# apollo3 register map
Vendor: Ambiq Micro; Series: Apollo; File version: 1.0
CPU: CM4 r1p0, little endian, MPU, FPU, 3 interrupt priority bits
Registers are 32-bit, read-write, reset 0x0 unless marked. A register's access mark holds for its fields unless they carry their own. Offsets are from the block's base; [hi:lo] are bit positions; {n}, {i} and the like mark numbered series; 'fields as' and 'values as' point back to an identical list.

## PWRCTRL — PWR Controller Register Bank
Base 0x40021000
0x00 SUPPLYSRC — Voltage Regulator Select Register
  [0] BLEBUCKEN — Enables and Selects the BLE Buck as the supply for the BLE power domain or for Burst LDO. It takes the initial value from Customer INFO space. Buck will be powered up only if there is an active request for BLEH domain or Burst mode and appropriate feature is allowed.
    1=EN (Enable the BLE Buck. value.); 0=DIS (Disable the BLE Buck. value.)
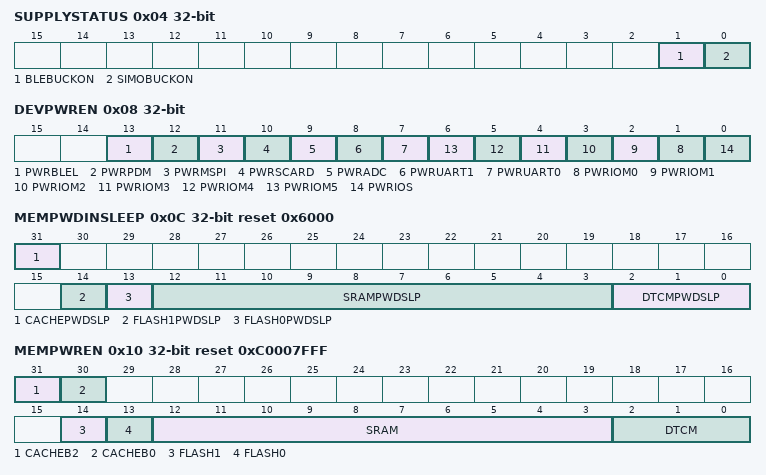
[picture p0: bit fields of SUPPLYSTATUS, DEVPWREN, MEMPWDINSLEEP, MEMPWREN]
0x04 SUPPLYSTATUS — Voltage Regulators status
  [1] BLEBUCKON — Indicates whether the BLE (if supported) domain and burst (if supported) domain is supplied from the LDO or the Buck. Buck will be powered up only if there is an active request for BLEH domain or Burst mode and appropriate reature is allowed.
    0=LDO (Indicates the the LDO is supplying the BLE/Burst power domain value.); 1=BUCK (Indicates the the Buck is supplying the BLE/Burst power domain value.)
  [0] SIMOBUCKON — Indicates whether the Core/Mem low-voltage domains are supplied from the LDO or the Buck.
    0=OFF (Indicates the the SIMO Buck is OFF. value.); 1=ON (Indicates the the SIMO Buck is ON. value.)
0x08 DEVPWREN — Device Power Enables
  [13] PWRBLEL — Power up BLE controller
    1=EN (Power up BLE controller value.); 0=DIS (Power down BLE controller value.)
  [12] PWRPDM — Power up PDM block
    1=EN (Power up PDM value.); 0=DIS (Power down PDM value.)
  [11] PWRMSPI — Power up MSPI Controller
    1=EN (Power up MSPI value.); 0=DIS (Power down MSPI value.)
  [10] PWRSCARD — Power up SCARD Controller
    1=EN (Power up SCARD value.); 0=DIS (Power down SCARD value.)
  [9] PWRADC — Power up ADC Digital Controller
    1=EN (Power up ADC value.); 0=DIS (Power Down ADC value.)
  [8] PWRUART1 — Power up UART Controller 1
    1=EN (Power up UART 1 value.); 0=DIS (Power down UART 1 value.)
  [7] PWRUART0 — Power up UART Controller 0
    1=EN (Power up UART 0 value.); 0=DIS (Power down UART 0 value.)
  [n+1] PWRIOM{n} (n=0..5) — Power up IO Master {n}
    1=EN (Power up IO Master {n} value.); 0=DIS (Power down IO Master {n} value.)
  [0] PWRIOS — Power up IO Slave
    1=EN (Power up IO slave value.); 0=DIS (Power down IO slave value.)
0x0C MEMPWDINSLEEP reset 0x6000 — Powerdown SRAM banks in Deep Sleep mode
  [31] CACHEPWDSLP — power down cache in deep sleep
    1=EN (Power down cache in deep sleep value.); 0=DIS (Retain cache in deep sleep value.)
  [14] FLASH1PWDSLP — Powerdown flash1 in deep sleep
    1=EN (Flash1 is powered down during deepsleep value.); 0=DIS (Flash1 is kept powered on during deepsleep value.)
  [13] FLASH0PWDSLP — Powerdown flash0 in deep sleep
    1=EN (Flash0 is powered down during deepsleep value.); 0=DIS (Flash0 is kept powered on during deepsleep value.)
  [12:3] SRAMPWDSLP — Selects which SRAM banks are powered down in deep sleep mode, causing the contents of the bank to be lost.
    0=NONE (All banks retained value.); 1=GROUP0 (SRAM GROUP0 powered down (64KB-96KB) value.); 2=GROUP1 (SRAM GROUP1 powered down (96KB-128KB) value.); 4=GROUP2 (SRAM GROUP2 powered down (128KB-160KB) value.); 8=GROUP3 (SRAM GROUP3 powered down (160KB-192KB) value.); 16=GROUP4 (SRAM GROUP4 powered down (192KB-224KB) value.); 32=GROUP5 (SRAM GROUP5 powered down (224KB-256KB) value.); 64=GROUP6 (SRAM GROUP6 powered down (256KB-288KB) value.); 128=GROUP7 (SRAM GROUP7 powered down (288KB-320KB) value.); 0x100=GROUP8 (SRAM GROUP8 powered down (320KB-352KB) value.); 0x200=GROUP9 (SRAM GROUP9 powered down (352KB-384KB) value.); 3=SRAM64K (Powerdown lower 64k SRAM (64KB-128KB) value.); 15=SRAM128K (Powerdown lower 128k SRAM (64KB-192KB) value.); 0x3FE=ALLBUTLOWER32K (All SRAM banks but lower 32k powered down (96KB-384KB). value.); 0x3FC=ALLBUTLOWER64K (All banks but lower 64k powered down. value.); 0x3F0=ALLBUTLOWER128K (All banks but lower 128k powered down. value.); 0x3FF=ALL (All banks powered down. value.)
  [2:0] DTCMPWDSLP — power down DTCM in deep sleep
    0=NONE (All DTCM retained value.); 1=GROUP0DTCM0 (Group0_DTCM0 powered down in deep sleep (0KB-8KB) value.); 2=GROUP0DTCM1 (Group0_DTCM1 powered down in deep sleep (8KB-32KB) value.); 3=GROUP0 (Both DTCMs in group0 are powered down in deep sleep (0KB-32KB) value.); 6=ALLBUTGROUP0DTCM0 (Group1 and Group0_DTCM1 are powered down in deep sleep (8KB-64KB) value.); 4=GROUP1 (Group1 DTCM powered down in deep sleep (32KB-64KB) value.); 7=ALL (All DTCMs powered down in deep sleep (0KB-64KB) value.)
0x10 MEMPWREN reset 0xC0007FFF — Enables individual banks of the MEMORY array
  [31] CACHEB2 — Power up Cache Bank 2. This works in conjunction with Cache enable from flash_cache module. To power up cache bank2, cache has to be enabled and this bit has to be set.
    1=EN (Power up Cache Bank 2 value.); 0=DIS (Power down Cache Bank 2 value.)
  [30] CACHEB0 — Power up Cache Bank 0. This works in conjunction with Cache enable from flash_cache module. To power up cache bank0, cache has to be enabled and this bit has to be set.
    1=EN (Power up Cache Bank 0 value.); 0=DIS (Power down Cache Bank 0 value.)
  [14] FLASH1 — Power up Flash1
    1=EN (Power up Flash1 value.); 0=DIS (Power down Flash1 value.)
  [13] FLASH0 — Power up Flash0
    1=EN (Power up Flash0 value.); 0=DIS (Power down Flash0 value.)
  [12:3] SRAM — Power up SRAM groups
    0=NONE (Do not power ON any of the SRAM banks value.); 1=GROUP0 (Power ON only SRAM group0 (0KB-32KB) value.); 2=GROUP1 (Power ON only SRAM group1 (32KB-64KB) value.); 4=GROUP2 (Power ON only SRAM group2 (64KB-96KB) value.); 8=GROUP3 (Power ON only SRAM group3 (96KB-128KB) value.); 16=GROUP4 (Power ON only SRAM group4 (128KB-160KB) value.); 32=GROUP5 (Power ON only SRAM group5 (160KB-192KB) value.); 64=GROUP6 (Power ON only SRAM group6 (192KB-224KB) value.); 128=GROUP7 (Power ON only SRAM group7 (224KB-256KB) value.); 0x100=GROUP8 (Power ON only SRAM group8 (256KB-288KB) value.); 0x200=GROUP9 (Power ON only SRAM group9 (288KB-320KB) value.); 3=SRAM64K (Power ON only lower 64k value.); 15=SRAM128K (Power ON only lower 128k value.); 255=SRAM256K (Power ON only lower 256k value.); 0x3FF=ALL (All SRAM banks (320K) powered ON value.)
  [2:0] DTCM — Power up DTCM
    0=NONE (Do not enable power to any DTCMs value.); 1=GROUP0DTCM0 (Power ON only GROUP0_DTCM0 value.); 2=GROUP0DTCM1 (Power ON only GROUP0_DTCM1 value.); 3=GROUP0 (Power ON only DTCMs in group0 value.); 4=GROUP1 (Power ON only DTCMs in group1 value.); 7=ALL (Power ON all DTCMs value.)
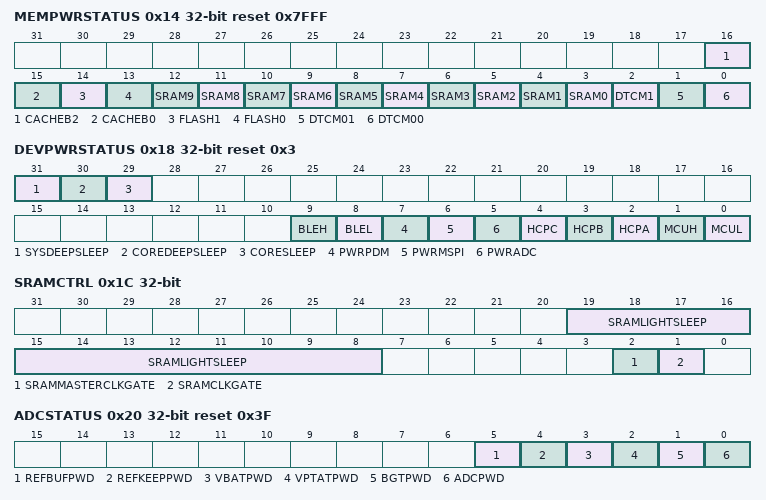
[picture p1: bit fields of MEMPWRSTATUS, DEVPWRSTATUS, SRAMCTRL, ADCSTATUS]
0x14 MEMPWRSTATUS reset 0x7FFF — Mem Power ON Status
  [16] CACHEB2 — This bit is 1 if power is supplied to Cache Bank 2
  [15] CACHEB0 — This bit is 1 if power is supplied to Cache Bank 0
  [14] FLASH1 — This bit is 1 if power is supplied to FLASH 1
  [13] FLASH0 — This bit is 1 if power is supplied to FLASH 0
  [n+3] SRAM{n} (n=0..9) — This bit is 1 if power is supplied to SRAM GROUP{n}
  [2] DTCM1 — This bit is 1 if power is supplied to DTCM GROUP1
  [1] DTCM01 — This bit is 1 if power is supplied to DTCM GROUP0_1
  [0] DTCM00 — This bit is 1 if power is supplied to DTCM GROUP0_0
0x18 DEVPWRSTATUS reset 0x3 — Device Power ON Status
  [31] SYSDEEPSLEEP — This bit is 1 if SYSTEM has been in Deep Sleep. Write '1' to this bit to clear it.
  [30] COREDEEPSLEEP — This bit is 1 if CORE has been in Deep Sleep. Write '1' to this bit to clear it.
  [29] CORESLEEP — This bit is 1 if CORE has been in SLEEP State. Write '1' to this bit to clear it.
  [9] BLEH — This bit is 1 if power is supplied to BLEH
  [8] BLEL — This bit is 1 if power is supplied to BLEL
  [7] PWRPDM — This bit is 1 if power is supplied to PDM
  [6] PWRMSPI — This bit is 1 if power is supplied to MSPI
  [5] PWRADC — This bit is 1 if power is supplied to ADC
  [4] HCPC — This bit is 1 if power is supplied to HCPC domain (IO MASTER4, 5, 6)
  [3] HCPB — This bit is 1 if power is supplied to HCPB domain (IO MASTER 0, 1, 2)
  [2] HCPA — This bit is 1 if power is supplied to HCPA domain (IO SLAVE, UART0, UART1, SCARD)
  [1] MCUH — This bit is 1 if power is supplied to MCUH
  [0] MCUL — This bit is 1 if power is supplied to MCUL
0x1C SRAMCTRL — SRAM Control register
  [19:8] SRAMLIGHTSLEEP — Light Sleep enable for each TCM/SRAM bank. When 1, corresponding bank will be put into light sleep. For optimal power, banks should be put into light sleep while the system is active but the bank has minimal or no accesses.
    255=ALL (Enable LIGHT SLEEP for ALL SRAMs value.); 0=DIS (Disables LIGHT SLEEP for ALL SRAMs value.)
  [2] SRAMMASTERCLKGATE — This bit is 1 when the master clock gate is enabled (top-level clock gate for entire SRAM block)
    1=EN (Enable Master SRAM Clock Gate value.); 0=DIS (Disables Master SRAM Clock Gating value.)
  [1] SRAMCLKGATE — This bit is 1 if clock gating is allowed for individual system SRAMs
    1=EN (Enable Individual SRAM Clock Gating value.); 0=DIS (Disables Individual SRAM Clock Gating value.)
0x20 ADCSTATUS reset 0x3F — Power Status Register for ADC Block
  [5] REFBUFPWD — This bit indicates that the ADC REFBUF is powered down
  [4] REFKEEPPWD — This bit indicates that the ADC REFKEEP is powered down
  [3] VBATPWD — This bit indicates that the ADC VBAT resistor divider is powered down
  [2] VPTATPWD — This bit indicates that the ADC temperature sensor input buffer is powered down
  [1] BGTPWD — This bit indicates that the ADC Band Gap is powered down
  [0] ADCPWD — This bit indicates that the ADC is powered down
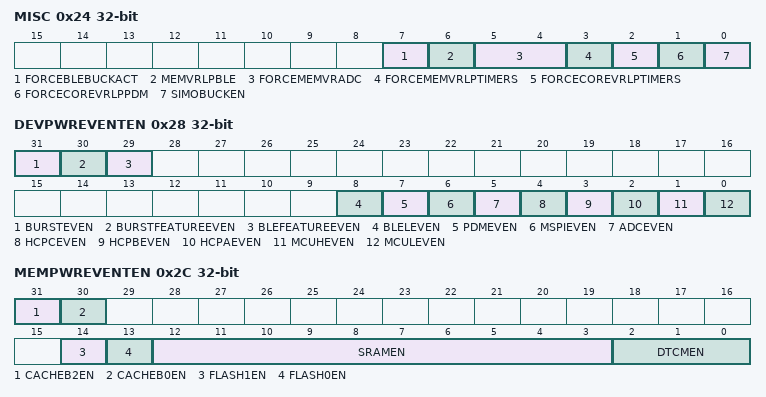
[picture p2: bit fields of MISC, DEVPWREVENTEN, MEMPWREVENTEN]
0x24 MISC — Power Optimization Control Bits
  [7] FORCEBLEBUCKACT — Control Bit to enable BLE Buck to be in active state when BLE Buck is enabled. Default behavior is to be in active only when Burst or BLEH power on are requested.
  [6] MEMVRLPBLE — Control Bit to let Mem VR go to lp mode in deep sleep even when BLEL or BLEH is powered on given none of the other domains require it.
    1=EN (Mem VR can go to lp mode even when BLE is powered on. value.); 0=DIS (Mem VR will stay in active mode when BLE is powered on. value.)
  [5:4] FORCEMEMVRADC — Control Bit to force mem VR to LP or ACT mode in deep sleep when ADC is powered ON. 0x3 results in picking LP mode.
    2=ACT (In this mode if all the other domains but ADC are powered down, mem VR will stay in ACT mode. value.); 1=LP (In this mode if all the other domains but ADC are powered down, mem VR will stay in LP mode. value.); 0=DIS (In this mode if all the other domains but ADC are powered down, mem VR will duty cycle between active and LP modes depending on ADC sampling. value.)
  [3] FORCEMEMVRLPTIMERS — Control Bit to force Mem VR to LP mode in deep sleep even when hfrc based ctimer or stimer is running.
  [2] FORCECOREVRLPTIMERS — Control Bit to force Core VR to LP mode in deep sleep even when hfrc based ctimer or stimer is running.
  [1] FORCECOREVRLPPDM — Control bit to enable the core VR to go into LP mode with HCPA/B/C/MSPI are powered off but PDM is powered on
  [0] SIMOBUCKEN — Enables and Selects the SIMO Buck as the supply for the low-voltage power domain. It takes the initial value from the bit set in Customer INFO space.
    1=EN (Enable the SIMO Buck value.); 0=DIS (Disable the SIMO Buck value.)
0x28 DEVPWREVENTEN — Event enable register to control which DEVPWRSTATUS bits are routed to event input of CPU.
  [31] BURSTEVEN — Control BURST status event
    1=EN (Enable BURST status event value.); 0=DIS (Disable BURST status event value.)
  [30] BURSTFEATUREEVEN — Control BURSTFEATURE status event
    1=EN (Enable BURSTFEATURE status event value.); 0=DIS (Disable BURSTFEATURE status event value.)
  [29] BLEFEATUREEVEN — Control BLEFEATURE status event
    1=EN (Enable BLEFEATURE status event value.); 0=DIS (Disable BLEFEATURE status event value.)
  [8] BLELEVEN — Control BLE power-on status event
    1=EN (Enable BLE power-on status event value.); 0=DIS (Disable BLE power-on status event value.)
  [7] PDMEVEN — Control PDM power-on status event
    1=EN (Enable PDM power-on status event value.); 0=DIS (Disable PDM power-on status event value.)
  [6] MSPIEVEN — Control MSPI power-on status event
    1=EN (Enable MSPI power-on status event value.); 0=DIS (Disable MSPI power-on status event value.)
  [5] ADCEVEN — Control ADC power-on status event
    1=EN (Enable ADC power-on status event value.); 0=DIS (Disable ADC power-on status event value.)
  [4] HCPCEVEN — Control HCPC power-on status event
    1=EN (Enable HCPC power-on status event value.); 0=DIS (Disable HCPC power-on status event value.)
  [3] HCPBEVEN — Control HCPB power-on status event
    1=EN (Enable HCPB power-on status event value.); 0=DIS (Disable HCPB power-on status event value.)
  [2] HCPAEVEN — Control HCPA power-on status event
    1=EN (Enable HCPA power-on status event value.); 0=DIS (Disable HCPA power-on status event value.)
  [1] MCUHEVEN — Control MCUH power-on status event
    1=EN (Enable MCHU power-on status event value.); 0=DIS (Disable MCUH power-on status event value.)
  [0] MCULEVEN — Control MCUL power-on status event
    1=EN (Enable MCUL power-on status event value.); 0=DIS (Disable MCUL power-on status event value.)
0x2C MEMPWREVENTEN — Event enable register to control which MEMPWRSTATUS bits are routed to event input of CPU.
  [31] CACHEB2EN — Control CACHEB2 power-on status event
    1=EN (Enable CACHE BANK 2 status event value.); 0=DIS (Disable CACHE BANK 2 status event value.)
  [30] CACHEB0EN — Control CACHE BANK 0 power-on status event
    1=EN (Enable CACHE BANK 0 status event value.); 0=DIS (Disable CACHE BANK 0 status event value.)
  [14] FLASH1EN — Control Flash power-on status event
    1=EN (Enable FLASH status event value.); 0=DIS (Disables FLASH status event value.)
  [13] FLASH0EN — Control Flash power-on status event
    values as FLASH1EN
  [12:3] SRAMEN — Control SRAM power-on status event
    0=NONE (Disable SRAM power-on status event value.); 1=GROUP0EN (Enable SRAM group0 (0KB-32KB) power on status event value.); 2=GROUP1EN (Enable SRAM group1 (32KB-64KB) power on status event value.); 4=GROUP2EN (Enable SRAM group2 (64KB-96KB) power on status event value.); 8=GROUP3EN (Enable SRAM group3 (96KB-128KB) power on status event value.); 16=GROUP4EN (Enable SRAM group4 (128KB-160KB) power on status event value.); 32=GROUP5EN (Enable SRAM group5 (160KB-192KB) power on status event value.); 64=GROUP6EN (Enable SRAM group6 (192KB-224KB) power on status event value.); 128=GROUP7EN (Enable SRAM group7 (224KB-256KB) power on status event value.); 0x100=GROUP8EN (Enable SRAM group8 (256KB-288KB) power on status event value.); 0x200=GROUP9EN (Enable SRAM group9 (288KB-320KB) power on status event value.)
  [2:0] DTCMEN — Enable DTCM power-on status event
    0=NONE (Do not enable DTCM power-on status event value.); 1=GROUP0DTCM0EN (Enable GROUP0_DTCM0 power on status event value.); 2=GROUP0DTCM1EN (Enable GROUP0_DTCM1 power on status event value.); 3=GROUP0EN (Enable DTCMs in group0 power on status event value.); 4=GROUP1EN (Enable DTCMs in group1 power on status event value.); 7=ALL (Enable all DTCM power on status event value.)
